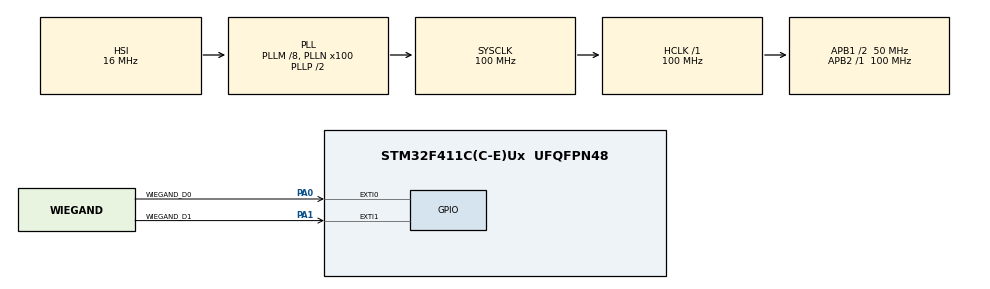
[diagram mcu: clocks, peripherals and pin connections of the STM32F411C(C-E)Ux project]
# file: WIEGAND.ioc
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Mcu.Family=STM32F4
Mcu.Name=STM32F411C(C-E)Ux
Mcu.Package=UFQFPN48
NVIC.PriorityGroup=NVIC_PRIORITYGROUP_4
PA0-WKUP.GPIO_Label=WIEGAND_D0
PA0-WKUP.GPIO_ModeDefaultEXTI=GPIO_MODE_IT_FALLING
PA0-WKUP.GPIO_PuPd=GPIO_PULLUP
PA0-WKUP.Signal=GPXTI0
PA1.GPIO_Label=WIEGAND_D1
PA1.GPIO_ModeDefaultEXTI=GPIO_MODE_IT_FALLING
PA1.GPIO_PuPd=GPIO_PULLUP
PA1.Signal=GPXTI1
PA13.Mode=Serial_Wire
PA13.Signal=SYS_JTMS-SWDIO
PA14.Mode=Serial_Wire
PA14.Signal=SYS_JTCK-SWCLK
PC14-OSC32_IN.Mode=LSE-External-Oscillator
PC14-OSC32_IN.Signal=RCC_OSC32_IN
PC15-OSC32_OUT.Mode=LSE-External-Oscillator
PC15-OSC32_OUT.Signal=RCC_OSC32_OUT
PH0\ -\ OSC_IN.Mode=HSE-External-Oscillator
PH0\ -\ OSC_IN.Signal=RCC_OSC_IN
PH1\ -\ OSC_OUT.Mode=HSE-External-Oscillator
PH1\ -\ OSC_OUT.Signal=RCC_OSC_OUT
ProjectManager.HeapSize=0x200
ProjectManager.StackSize=0x400
ProjectManager.TargetToolchain=STM32CubeIDE
RCC.48MHZClocksFreq_Value=50000000
RCC.AHBFreq_Value=100000000
RCC.APB1CLKDivider=RCC_HCLK_DIV2
RCC.APB1Freq_Value=50000000
RCC.APB1TimFreq_Value=100000000
RCC.APB2Freq_Value=100000000
RCC.APB2TimFreq_Value=100000000
RCC.CortexFreq_Value=100000000
RCC.HCLKFreq_Value=100000000
RCC.HSE_VALUE=25000000
RCC.HSI_VALUE=16000000
RCC.PLLM=8
RCC.PLLN=100
RCC.SYSCLKFreq_VALUE=100000000
RCC.SYSCLKSource=RCC_SYSCLKSOURCE_PLLCLK
RCC.VCOOutputFreq_Value=200000000
TIM11.Period=100
TIM11.Prescaler=100
VP_TIM11_VS_ClockSourceINT.Mode=Enable_Timer
board=custom

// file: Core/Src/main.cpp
/* USER CODE BEGIN Header */
/**
  ******************************************************************************
  * @file           : main.cpp
  * @brief          : Main program body
  ******************************************************************************
  * @attention
  *
  * Copyright (c) 2024 STMicroelectronics.
  * All rights reserved.
  *
  * This software is licensed under terms that can be found in the LICENSE file
  * in the root directory of this software component.
  * If no LICENSE file comes with this software, it is provided AS-IS.
  *
  ******************************************************************************
  */
/* USER CODE END Header */
#include "main.h"

/* USER CODE BEGIN Includes */
#include "Interface/wiegand_handler.h"

/* USER CODE END Includes */

TIM_HandleTypeDef htim11;

/* USER CODE BEGIN PV */
WIEGAND reader(WIEGAND_LENGTH_34_BITS, GPIO_PIN_0, GPIO_PIN_1, &htim11, 100);
//WIEGAND reader(WIEGAND_LENGTH_26_BITS, GPIO_PIN_0, GPIO_PIN_1, &htim11, 100);

/* USER CODE END PV */

void SystemClock_Config(void);
static void MX_GPIO_Init(void);
static void MX_TIM11_Init(void);

int main(void)
{

  /* MCU Configuration--------------------------------------------------------*/

  /* Reset of all peripherals, Initializes the Flash interface and the Systick. */
  HAL_Init();

  /* Configure the system clock */
  SystemClock_Config();

  /* Initialize all configured peripherals */
  MX_GPIO_Init();
  MX_TIM11_Init();

  /* Infinite loop */
  while (1)
  {
	  reader.start();
	  if(reader.data.ready)
	  {
		  // data contains facility code and card id
		  //
		  // card id 		= data.card_id
		  // facility code 	= data.fac_code
		  //
		  // validate your data here
		  // find data.card_id from your stored memory
		  // or send data.card_id to another device to validate
		  // you can also use the debugger to check the data received from wiegand device

		  reader.data.ready = false; // set to 'data.ready' after all of the implimentations.
	  }

  }
}

void SystemClock_Config(void)
{
  RCC_OscInitTypeDef RCC_OscInitStruct = {0};
  RCC_ClkInitTypeDef RCC_ClkInitStruct = {0};

  /** Configure the main internal regulator output voltage
  */
  __HAL_RCC_PWR_CLK_ENABLE();
  __HAL_PWR_VOLTAGESCALING_CONFIG(PWR_REGULATOR_VOLTAGE_SCALE1);

  /** Initializes the RCC Oscillators according to the specified parameters
  * in the RCC_OscInitTypeDef structure.
  */
  RCC_OscInitStruct.OscillatorType = RCC_OSCILLATORTYPE_HSI;
  RCC_OscInitStruct.HSIState = RCC_HSI_ON;
  RCC_OscInitStruct.HSICalibrationValue = RCC_HSICALIBRATION_DEFAULT;
  RCC_OscInitStruct.PLL.PLLState = RCC_PLL_ON;
  RCC_OscInitStruct.PLL.PLLSource = RCC_PLLSOURCE_HSI;
  RCC_OscInitStruct.PLL.PLLM = 8;
  RCC_OscInitStruct.PLL.PLLN = 100;
  RCC_OscInitStruct.PLL.PLLP = RCC_PLLP_DIV2;
  RCC_OscInitStruct.PLL.PLLQ = 4;
  if (HAL_RCC_OscConfig(&RCC_OscInitStruct) != HAL_OK)
  {
    Error_Handler();
  }

  /** Initializes the CPU, AHB and APB buses clocks
  */
  RCC_ClkInitStruct.ClockType = RCC_CLOCKTYPE_HCLK|RCC_CLOCKTYPE_SYSCLK
                              |RCC_CLOCKTYPE_PCLK1|RCC_CLOCKTYPE_PCLK2;
  RCC_ClkInitStruct.SYSCLKSource = RCC_SYSCLKSOURCE_PLLCLK;
  RCC_ClkInitStruct.AHBCLKDivider = RCC_SYSCLK_DIV1;
  RCC_ClkInitStruct.APB1CLKDivider = RCC_HCLK_DIV2;
  RCC_ClkInitStruct.APB2CLKDivider = RCC_HCLK_DIV1;

  if (HAL_RCC_ClockConfig(&RCC_ClkInitStruct, FLASH_LATENCY_3) != HAL_OK)
  {
    Error_Handler();
  }
}

static void MX_TIM11_Init(void)
{

  htim11.Instance = TIM11;
  htim11.Init.Prescaler = 100;
  htim11.Init.CounterMode = TIM_COUNTERMODE_UP;
  htim11.Init.Period = 100;
  htim11.Init.ClockDivision = TIM_CLOCKDIVISION_DIV1;
  htim11.Init.AutoReloadPreload = TIM_AUTORELOAD_PRELOAD_DISABLE;
  if (HAL_TIM_Base_Init(&htim11) != HAL_OK)
  {
    Error_Handler();
  }

}

static void MX_GPIO_Init(void)
{
  GPIO_InitTypeDef GPIO_InitStruct = {0};

  /* GPIO Ports Clock Enable */
  __HAL_RCC_GPIOC_CLK_ENABLE();
  __HAL_RCC_GPIOH_CLK_ENABLE();
  __HAL_RCC_GPIOA_CLK_ENABLE();

  /*Configure GPIO pins : WIEGAND_D0_Pin WIEGAND_D1_Pin */
  GPIO_InitStruct.Pin = WIEGAND_D0_Pin|WIEGAND_D1_Pin;
  GPIO_InitStruct.Mode = GPIO_MODE_IT_FALLING;
  GPIO_InitStruct.Pull = GPIO_PULLUP;
  HAL_GPIO_Init(GPIOA, &GPIO_InitStruct);

}

/* USER CODE BEGIN 4 */
void HAL_TIM_PeriodElapsedCallback(TIM_HandleTypeDef *htim)
{
	reader.timer_callback(htim);
}

void HAL_GPIO_EXTI_Callback(uint16_t GPIO_Pin)
{
	 reader.exti_callback(GPIO_Pin);
}
/* USER CODE END 4 */

void Error_Handler(void)
{
  __disable_irq();
  while (1)
  {
  }
}
